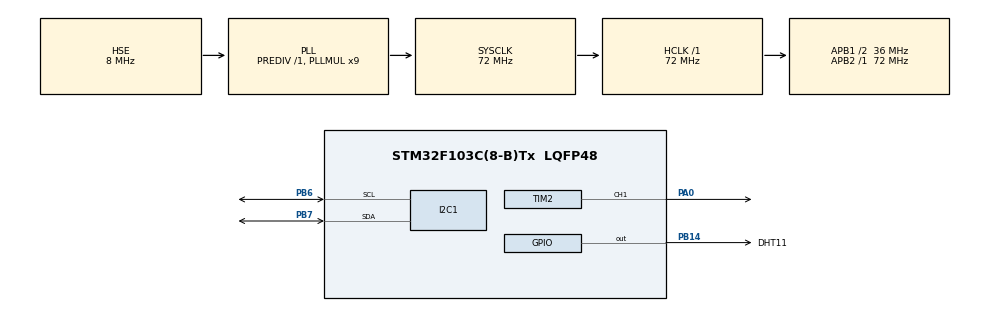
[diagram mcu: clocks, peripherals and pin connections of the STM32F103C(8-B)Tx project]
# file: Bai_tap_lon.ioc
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Mcu.Family=STM32F1
Mcu.Name=STM32F103C(8-B)Tx
Mcu.Package=LQFP48
NVIC.PriorityGroup=NVIC_PRIORITYGROUP_4
PA0-WKUP.Signal=S_TIM2_CH1_ETR
PA13.Mode=Serial_Wire
PA13.Signal=SYS_JTMS-SWDIO
PA14.Mode=Serial_Wire
PA14.Signal=SYS_JTCK-SWCLK
PB14.GPIO_Label=DHT11
PB14.Signal=GPIO_Output
PB6.Mode=I2C
PB6.Signal=I2C1_SCL
PB7.Mode=I2C
PB7.Signal=I2C1_SDA
PD0-OSC_IN.Mode=HSE-External-Oscillator
PD0-OSC_IN.Signal=RCC_OSC_IN
PD1-OSC_OUT.Mode=HSE-External-Oscillator
PD1-OSC_OUT.Signal=RCC_OSC_OUT
ProjectManager.HeapSize=0x200
ProjectManager.StackSize=0x400
ProjectManager.TargetToolchain=MDK-ARM V5.32
RCC.AHBFreq_Value=72000000
RCC.APB1CLKDivider=RCC_HCLK_DIV2
RCC.APB1Freq_Value=36000000
RCC.APB1TimFreq_Value=72000000
RCC.APB2Freq_Value=72000000
RCC.APB2TimFreq_Value=72000000
RCC.HCLKFreq_Value=72000000
RCC.PLLMUL=RCC_PLL_MUL9
RCC.PLLSourceVirtual=RCC_PLLSOURCE_HSE
RCC.SYSCLKFreq_VALUE=72000000
RCC.SYSCLKSource=RCC_SYSCLKSOURCE_PLLCLK
RCC.USBFreq_Value=72000000
SH.S_TIM2_CH1_ETR.0=TIM2_CH1,PWM Generation1 CH1
TIM2.AutoReloadPreload=TIM_AUTORELOAD_PRELOAD_ENABLE
TIM2.Channel-PWM\ Generation1\ CH1=TIM_CHANNEL_1
TIM2.Period=1999
TIM2.Prescaler=799
TIM2.Pulse-PWM\ Generation1\ CH1=100
TIM4.Period=65534
TIM4.Prescaler=71
VP_TIM1_VS_ClockSourceINT.Mode=Internal
VP_TIM2_VS_ClockSourceINT.Mode=Internal
VP_TIM4_VS_ClockSourceINT.Mode=Internal
board=custom

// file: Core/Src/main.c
/* USER CODE BEGIN Header */
/**
  ******************************************************************************
  * @file           : main.c
  * @brief          : Main program body
  ******************************************************************************
  * @attention
  *
  * Copyright (c) 2022 STMicroelectronics.
  * All rights reserved.
  *
  * This software is licensed under terms that can be found in the LICENSE file
  * in the root directory of this software component.
  * If no LICENSE file comes with this software, it is provided AS-IS.
  *
  ******************************************************************************
  */
/* USER CODE END Header */
#include "main.h"

/* USER CODE BEGIN Includes */
#include "DHT11.h"
#include "delay_timer.h"
#include "DS3231.h"
/* USER CODE END Includes */

/* USER CODE BEGIN PTD */
uint8_t device=0;
DS3231_Name DS3231;
DHT_Name DHT1;
/* USER CODE END PTD */

I2C_HandleTypeDef hi2c1;

TIM_HandleTypeDef htim1;
TIM_HandleTypeDef htim2;
TIM_HandleTypeDef htim4;

void SystemClock_Config(void);
static void MX_GPIO_Init(void);
static void MX_TIM4_Init(void);
static void MX_TIM2_Init(void);
static void MX_I2C1_Init(void);
static void MX_TIM1_Init(void);

int main(void)
{

  /* MCU Configuration--------------------------------------------------------*/

  /* Reset of all peripherals, Initializes the Flash interface and the Systick. */
  HAL_Init();

  /* Configure the system clock */
  SystemClock_Config();

  /* Initialize all configured peripherals */
  MX_GPIO_Init();
  MX_TIM4_Init();
  MX_TIM2_Init();
  MX_I2C1_Init();
  MX_TIM1_Init();
  /* USER CODE BEGIN 2 */
	/*for(uint8_t i=0;i<255;i++)
	{
		if(HAL_I2C_IsDeviceReady(&hi2c1,i,1,100)==HAL_OK)
			device=i;
	}
	DS3231_Init(&DS3231,&hi2c1);
	DS3231_SetTime(&DS3231,21,26,24);
	DS3231_SetDate(&DS3231,3,6,12,22);
	*/
	//HAL_TIM_PWM_Start(&htim2,TIM_CHANNEL_1);
	DHT_Init(&DHT1,&htim4,DHT11_GPIO_Port,DHT11_Pin);
  /* USER CODE END 2 */

  /* Infinite loop */
  while (1)
  {

    /* USER CODE BEGIN 3 */
		//DS3231_GetTime(&DS3231);
		//DS3231_GetDate(&DS3231);

		DHT_ReadTempHum(&DHT1);
		HAL_Delay(200);
		//HAL_Delay(1000);

			//__HAL_TIM_SET_COMPARE(&htim2,TIM_CHANNEL_1,200);
	}
  /* USER CODE END 3 */
}

void SystemClock_Config(void)
{
  RCC_OscInitTypeDef RCC_OscInitStruct = {0};
  RCC_ClkInitTypeDef RCC_ClkInitStruct = {0};

  /** Initializes the RCC Oscillators according to the specified parameters
  * in the RCC_OscInitTypeDef structure.
  */
  RCC_OscInitStruct.OscillatorType = RCC_OSCILLATORTYPE_HSE;
  RCC_OscInitStruct.HSEState = RCC_HSE_ON;
  RCC_OscInitStruct.HSEPredivValue = RCC_HSE_PREDIV_DIV1;
  RCC_OscInitStruct.HSIState = RCC_HSI_ON;
  RCC_OscInitStruct.PLL.PLLState = RCC_PLL_ON;
  RCC_OscInitStruct.PLL.PLLSource = RCC_PLLSOURCE_HSE;
  RCC_OscInitStruct.PLL.PLLMUL = RCC_PLL_MUL9;
  if (HAL_RCC_OscConfig(&RCC_OscInitStruct) != HAL_OK)
  {
    Error_Handler();
  }

  /** Initializes the CPU, AHB and APB buses clocks
  */
  RCC_ClkInitStruct.ClockType = RCC_CLOCKTYPE_HCLK|RCC_CLOCKTYPE_SYSCLK
                              |RCC_CLOCKTYPE_PCLK1|RCC_CLOCKTYPE_PCLK2;
  RCC_ClkInitStruct.SYSCLKSource = RCC_SYSCLKSOURCE_PLLCLK;
  RCC_ClkInitStruct.AHBCLKDivider = RCC_SYSCLK_DIV1;
  RCC_ClkInitStruct.APB1CLKDivider = RCC_HCLK_DIV2;
  RCC_ClkInitStruct.APB2CLKDivider = RCC_HCLK_DIV1;

  if (HAL_RCC_ClockConfig(&RCC_ClkInitStruct, FLASH_LATENCY_2) != HAL_OK)
  {
    Error_Handler();
  }
}

static void MX_I2C1_Init(void)
{

  hi2c1.Instance = I2C1;
  hi2c1.Init.ClockSpeed = 100000;
  hi2c1.Init.DutyCycle = I2C_DUTYCYCLE_2;
  hi2c1.Init.OwnAddress1 = 0;
  hi2c1.Init.AddressingMode = I2C_ADDRESSINGMODE_7BIT;
  hi2c1.Init.DualAddressMode = I2C_DUALADDRESS_DISABLE;
  hi2c1.Init.OwnAddress2 = 0;
  hi2c1.Init.GeneralCallMode = I2C_GENERALCALL_DISABLE;
  hi2c1.Init.NoStretchMode = I2C_NOSTRETCH_DISABLE;
  if (HAL_I2C_Init(&hi2c1) != HAL_OK)
  {
    Error_Handler();
  }

}

static void MX_TIM1_Init(void)
{

  TIM_ClockConfigTypeDef sClockSourceConfig = {0};
  TIM_MasterConfigTypeDef sMasterConfig = {0};

  htim1.Instance = TIM1;
  htim1.Init.Prescaler = 0;
  htim1.Init.CounterMode = TIM_COUNTERMODE_UP;
  htim1.Init.Period = 65535;
  htim1.Init.ClockDivision = TIM_CLOCKDIVISION_DIV1;
  htim1.Init.RepetitionCounter = 0;
  htim1.Init.AutoReloadPreload = TIM_AUTORELOAD_PRELOAD_DISABLE;
  if (HAL_TIM_Base_Init(&htim1) != HAL_OK)
  {
    Error_Handler();
  }
  sClockSourceConfig.ClockSource = TIM_CLOCKSOURCE_INTERNAL;
  if (HAL_TIM_ConfigClockSource(&htim1, &sClockSourceConfig) != HAL_OK)
  {
    Error_Handler();
  }
  sMasterConfig.MasterOutputTrigger = TIM_TRGO_RESET;
  sMasterConfig.MasterSlaveMode = TIM_MASTERSLAVEMODE_DISABLE;
  if (HAL_TIMEx_MasterConfigSynchronization(&htim1, &sMasterConfig) != HAL_OK)
  {
    Error_Handler();
  }

}

static void MX_TIM2_Init(void)
{

  TIM_ClockConfigTypeDef sClockSourceConfig = {0};
  TIM_MasterConfigTypeDef sMasterConfig = {0};
  TIM_OC_InitTypeDef sConfigOC = {0};

  htim2.Instance = TIM2;
  htim2.Init.Prescaler = 799;
  htim2.Init.CounterMode = TIM_COUNTERMODE_UP;
  htim2.Init.Period = 1999;
  htim2.Init.ClockDivision = TIM_CLOCKDIVISION_DIV1;
  htim2.Init.AutoReloadPreload = TIM_AUTORELOAD_PRELOAD_ENABLE;
  if (HAL_TIM_Base_Init(&htim2) != HAL_OK)
  {
    Error_Handler();
  }
  sClockSourceConfig.ClockSource = TIM_CLOCKSOURCE_INTERNAL;
  if (HAL_TIM_ConfigClockSource(&htim2, &sClockSourceConfig) != HAL_OK)
  {
    Error_Handler();
  }
  if (HAL_TIM_PWM_Init(&htim2) != HAL_OK)
  {
    Error_Handler();
  }
  sMasterConfig.MasterOutputTrigger = TIM_TRGO_RESET;
  sMasterConfig.MasterSlaveMode = TIM_MASTERSLAVEMODE_DISABLE;
  if (HAL_TIMEx_MasterConfigSynchronization(&htim2, &sMasterConfig) != HAL_OK)
  {
    Error_Handler();
  }
  sConfigOC.OCMode = TIM_OCMODE_PWM1;
  sConfigOC.Pulse = 100;
  sConfigOC.OCPolarity = TIM_OCPOLARITY_HIGH;
  sConfigOC.OCFastMode = TIM_OCFAST_DISABLE;
  if (HAL_TIM_PWM_ConfigChannel(&htim2, &sConfigOC, TIM_CHANNEL_1) != HAL_OK)
  {
    Error_Handler();
  }
  HAL_TIM_MspPostInit(&htim2);

}

static void MX_TIM4_Init(void)
{

  TIM_ClockConfigTypeDef sClockSourceConfig = {0};
  TIM_MasterConfigTypeDef sMasterConfig = {0};

  htim4.Instance = TIM4;
  htim4.Init.Prescaler = 71;
  htim4.Init.CounterMode = TIM_COUNTERMODE_UP;
  htim4.Init.Period = 65534;
  htim4.Init.ClockDivision = TIM_CLOCKDIVISION_DIV1;
  htim4.Init.AutoReloadPreload = TIM_AUTORELOAD_PRELOAD_DISABLE;
  if (HAL_TIM_Base_Init(&htim4) != HAL_OK)
  {
    Error_Handler();
  }
  sClockSourceConfig.ClockSource = TIM_CLOCKSOURCE_INTERNAL;
  if (HAL_TIM_ConfigClockSource(&htim4, &sClockSourceConfig) != HAL_OK)
  {
    Error_Handler();
  }
  sMasterConfig.MasterOutputTrigger = TIM_TRGO_RESET;
  sMasterConfig.MasterSlaveMode = TIM_MASTERSLAVEMODE_DISABLE;
  if (HAL_TIMEx_MasterConfigSynchronization(&htim4, &sMasterConfig) != HAL_OK)
  {
    Error_Handler();
  }

}

static void MX_GPIO_Init(void)
{
  GPIO_InitTypeDef GPIO_InitStruct = {0};

  /* GPIO Ports Clock Enable */
  __HAL_RCC_GPIOD_CLK_ENABLE();
  __HAL_RCC_GPIOA_CLK_ENABLE();
  __HAL_RCC_GPIOB_CLK_ENABLE();

  /*Configure GPIO pin Output Level */
  HAL_GPIO_WritePin(DHT11_GPIO_Port, DHT11_Pin, GPIO_PIN_RESET);

  /*Configure GPIO pin : DHT11_Pin */
  GPIO_InitStruct.Pin = DHT11_Pin;
  GPIO_InitStruct.Mode = GPIO_MODE_OUTPUT_PP;
  GPIO_InitStruct.Pull = GPIO_NOPULL;
  GPIO_InitStruct.Speed = GPIO_SPEED_FREQ_LOW;
  HAL_GPIO_Init(DHT11_GPIO_Port, &GPIO_InitStruct);

}

void Error_Handler(void)
{
  __disable_irq();
  while (1)
  {
  }
}
